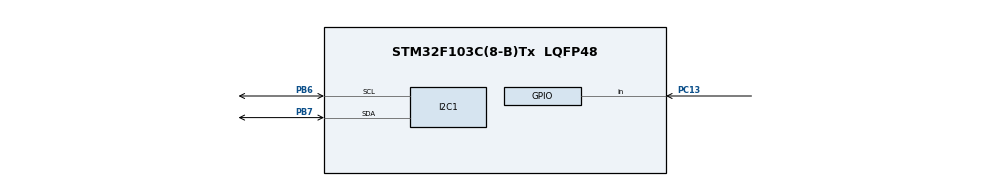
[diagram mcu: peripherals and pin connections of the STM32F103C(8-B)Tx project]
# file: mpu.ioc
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Mcu.Family=STM32F1
Mcu.Name=STM32F103C(8-B)Tx
Mcu.Package=LQFP48
NVIC.PriorityGroup=NVIC_PRIORITYGROUP_4
NVIC.TIM4_IRQn=true\:0\:0\:false\:false\:true\:true\:true
PA13.Mode=Serial_Wire
PA13.Signal=SYS_JTMS-SWDIO
PA14.Mode=Serial_Wire
PA14.Signal=SYS_JTCK-SWCLK
PB6.Mode=I2C
PB6.Signal=I2C1_SCL
PB7.Mode=I2C
PB7.Signal=I2C1_SDA
PC13-TAMPER-RTC.Signal=GPIO_Input
PD0-OSC_IN.Mode=HSE-External-Oscillator
PD0-OSC_IN.Signal=RCC_OSC_IN
PD1-OSC_OUT.Mode=HSE-External-Oscillator
PD1-OSC_OUT.Signal=RCC_OSC_OUT
ProjectManager.HeapSize=0x200
ProjectManager.StackSize=0x400
ProjectManager.TargetToolchain=STM32CubeIDE
RCC.APB1Freq_Value=8000000
RCC.APB2Freq_Value=8000000
VP_TIM4_VS_ClockSourceINT.Mode=Internal
board=custom

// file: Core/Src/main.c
/* USER CODE BEGIN Header */
/**
  ******************************************************************************
  * @file           : main.c
  * @brief          : Main program body
  ******************************************************************************
  * @attention
  *
  * <h2><center>&copy; Copyright (c) 2020 STMicroelectronics.
  * All rights reserved.</center></h2>
  *
  * This software component is licensed by ST under BSD 3-Clause license,
  * the "License"; You may not use this file except in compliance with the
  * License. You may obtain a copy of the License at:
  *                        opensource.org/licenses/BSD-3-Clause
  *
  ******************************************************************************
  */
/* USER CODE END Header */
#include "main.h"

/* USER CODE BEGIN Includes */
#define MPU6050_ADDR 0xD0

#define SMPLRT_DIV_REG 0x19
#define GYRO_CONFIG_REG 0x1B
#define ACCEL_CONFIG_REG 0x1C
#define ACCEL_XOUT_H_REG 0x3B
#define TEMP_OUT_H_REG 0x41
#define GYRO_XOUT_H_REG 0x43
#define PWR_MGMT_1_REG 0x6B
#define WHO_AM_I_REG 0x75
/* USER CODE END Includes */

I2C_HandleTypeDef hi2c1;

TIM_HandleTypeDef htim4;

/* USER CODE BEGIN PV */

int16_t Accel_X_RAW = 0;
int16_t Accel_Y_RAW = 0;
int16_t Accel_Z_RAW = 0;

int16_t Gyro_X_RAW = 0;
int16_t Gyro_Y_RAW = 0;
int16_t Gyro_Z_RAW = 0;

float Ax, Ay, Az, Gx, Gy, Gz;

void MPU6050_Init(void){
	uint8_t data, check;

	for(uint8_t i = 190; i < 220; i++){
		HAL_I2C_Mem_Read (&hi2c1, i,WHO_AM_I_REG,1, &check, 1, 1000);
		check;
	}

	if( check == 104){
		data = 0;
		HAL_I2C_Mem_Write(&hi2c1, MPU6050_ADDR, PWR_MGMT_1_REG, 1,&data, 1, 1000);

		// Set DATA RATE of 1KHz by writing SMPLRT_DIV register
		data = 0x07;
		HAL_I2C_Mem_Write(&hi2c1, MPU6050_ADDR, SMPLRT_DIV_REG, 1, &data, 1, 1000);

		// Set accelerometer configuration in ACCEL_CONFIG Register
		// XA_ST=0,YA_ST=0,ZA_ST=0, FS_SEL=0 -> ± 2g
		data = 0x00;
		HAL_I2C_Mem_Write(&hi2c1, MPU6050_ADDR, ACCEL_CONFIG_REG, 1, &data, 1, 1000);

		// Set Gyroscopic configuration in GYRO_CONFIG Register
		// XG_ST=0,YG_ST=0,ZG_ST=0, FS_SEL=0 -> ± 250 °/s
		data = 0x00;
		HAL_I2C_Mem_Write(&hi2c1, MPU6050_ADDR, GYRO_CONFIG_REG, 1, &data, 1, 1000);
	}
}

void MPU6050_Read_Accel (void)
{
	uint8_t Rec_Data[6];

	// Read 6 BYTES of data starting from ACCEL_XOUT_H register

	HAL_I2C_Mem_Read (&hi2c1, MPU6050_ADDR, ACCEL_XOUT_H_REG, 1, Rec_Data, 6, 1000);

	Accel_X_RAW = (int16_t)(Rec_Data[0] << 8 | Rec_Data [1]);
	Accel_Y_RAW = (int16_t)(Rec_Data[2] << 8 | Rec_Data [3]);
	Accel_Z_RAW = (int16_t)(Rec_Data[4] << 8 | Rec_Data [5]);

	/*** convert the RAW values into acceleration in 'g'
		 we have to divide according to the Full scale value set in FS_SEL
		 I have configured FS_SEL = 0. So I am dividing by 16384.0
		 for more details check ACCEL_CONFIG Register              ****/

	Ax = Accel_X_RAW/16384.0;
	Ay = Accel_Y_RAW/16384.0;
	Az = Accel_Z_RAW/16384.0;
}

/* USER CODE END PV */

void SystemClock_Config(void);
static void MX_GPIO_Init(void);
static void MX_I2C1_Init(void);
static void MX_TIM4_Init(void);

int main(void)
{

  /* MCU Configuration--------------------------------------------------------*/

  /* Reset of all peripherals, Initializes the Flash interface and the Systick. */
  HAL_Init();

  /* Configure the system clock */
  SystemClock_Config();

  /* Initialize all configured peripherals */
  MX_GPIO_Init();
  MX_I2C1_Init();
  MX_TIM4_Init();
  /* USER CODE BEGIN 2 */
  MPU6050_Init();

  /* USER CODE END 2 */

  /* Infinite loop */
  while (1)
  {

    /* USER CODE BEGIN 3 */
	  HAL_Delay(100);
	  MPU6050_Read_Accel();
	  Ax;
	  Ay;
	  Az;

  }
  /* USER CODE END 3 */
}

void SystemClock_Config(void)
{
  RCC_OscInitTypeDef RCC_OscInitStruct = {0};
  RCC_ClkInitTypeDef RCC_ClkInitStruct = {0};

  /** Initializes the RCC Oscillators according to the specified parameters
  * in the RCC_OscInitTypeDef structure.
  */
  RCC_OscInitStruct.OscillatorType = RCC_OSCILLATORTYPE_HSI;
  RCC_OscInitStruct.HSIState = RCC_HSI_ON;
  RCC_OscInitStruct.HSICalibrationValue = RCC_HSICALIBRATION_DEFAULT;
  RCC_OscInitStruct.PLL.PLLState = RCC_PLL_NONE;
  if (HAL_RCC_OscConfig(&RCC_OscInitStruct) != HAL_OK)
  {
    Error_Handler();
  }
  /** Initializes the CPU, AHB and APB buses clocks
  */
  RCC_ClkInitStruct.ClockType = RCC_CLOCKTYPE_HCLK|RCC_CLOCKTYPE_SYSCLK
                              |RCC_CLOCKTYPE_PCLK1|RCC_CLOCKTYPE_PCLK2;
  RCC_ClkInitStruct.SYSCLKSource = RCC_SYSCLKSOURCE_HSI;
  RCC_ClkInitStruct.AHBCLKDivider = RCC_SYSCLK_DIV1;
  RCC_ClkInitStruct.APB1CLKDivider = RCC_HCLK_DIV1;
  RCC_ClkInitStruct.APB2CLKDivider = RCC_HCLK_DIV1;

  if (HAL_RCC_ClockConfig(&RCC_ClkInitStruct, FLASH_LATENCY_0) != HAL_OK)
  {
    Error_Handler();
  }
}

static void MX_I2C1_Init(void)
{

  hi2c1.Instance = I2C1;
  hi2c1.Init.ClockSpeed = 100000;
  hi2c1.Init.DutyCycle = I2C_DUTYCYCLE_2;
  hi2c1.Init.OwnAddress1 = 0;
  hi2c1.Init.AddressingMode = I2C_ADDRESSINGMODE_7BIT;
  hi2c1.Init.DualAddressMode = I2C_DUALADDRESS_DISABLE;
  hi2c1.Init.OwnAddress2 = 0;
  hi2c1.Init.GeneralCallMode = I2C_GENERALCALL_DISABLE;
  hi2c1.Init.NoStretchMode = I2C_NOSTRETCH_DISABLE;
  if (HAL_I2C_Init(&hi2c1) != HAL_OK)
  {
    Error_Handler();
  }

}

static void MX_TIM4_Init(void)
{

  TIM_ClockConfigTypeDef sClockSourceConfig = {0};
  TIM_MasterConfigTypeDef sMasterConfig = {0};

  htim4.Instance = TIM4;
  htim4.Init.Prescaler = 0;
  htim4.Init.CounterMode = TIM_COUNTERMODE_UP;
  htim4.Init.Period = 65535;
  htim4.Init.ClockDivision = TIM_CLOCKDIVISION_DIV1;
  htim4.Init.AutoReloadPreload = TIM_AUTORELOAD_PRELOAD_DISABLE;
  if (HAL_TIM_Base_Init(&htim4) != HAL_OK)
  {
    Error_Handler();
  }
  sClockSourceConfig.ClockSource = TIM_CLOCKSOURCE_INTERNAL;
  if (HAL_TIM_ConfigClockSource(&htim4, &sClockSourceConfig) != HAL_OK)
  {
    Error_Handler();
  }
  sMasterConfig.MasterOutputTrigger = TIM_TRGO_RESET;
  sMasterConfig.MasterSlaveMode = TIM_MASTERSLAVEMODE_DISABLE;
  if (HAL_TIMEx_MasterConfigSynchronization(&htim4, &sMasterConfig) != HAL_OK)
  {
    Error_Handler();
  }

}

static void MX_GPIO_Init(void)
{
  GPIO_InitTypeDef GPIO_InitStruct = {0};

  /* GPIO Ports Clock Enable */
  __HAL_RCC_GPIOC_CLK_ENABLE();
  __HAL_RCC_GPIOD_CLK_ENABLE();
  __HAL_RCC_GPIOA_CLK_ENABLE();
  __HAL_RCC_GPIOB_CLK_ENABLE();

  /*Configure GPIO pin : PC13 */
  GPIO_InitStruct.Pin = GPIO_PIN_13;
  GPIO_InitStruct.Mode = GPIO_MODE_INPUT;
  GPIO_InitStruct.Pull = GPIO_NOPULL;
  HAL_GPIO_Init(GPIOC, &GPIO_InitStruct);

}

void Error_Handler(void)
{
}

/************************ (C) COPYRIGHT STMicroelectronics *****END OF FILE****/
